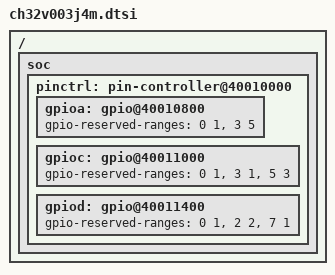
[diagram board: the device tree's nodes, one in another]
/*
 * Copyright (c) 2024 Michael Hope
 *
 * SPDX-License-Identifier: Apache-2.0
 */

#include <wch/ch32v0/ch32v003.dtsi>

/ {
	soc {
		pinctrl: pin-controller@40010000 {
			gpioa: gpio@40010800 {
				gpio-reserved-ranges = <0 1>, <3 5>;
			};

			gpioc: gpio@40011000 {
				gpio-reserved-ranges = <0 1>, <3 1>, <5 3>;
			};

			gpiod: gpio@40011400 {
				gpio-reserved-ranges = <0 1>, <2 2>, <7 1>;
			};
		};
	};
};
